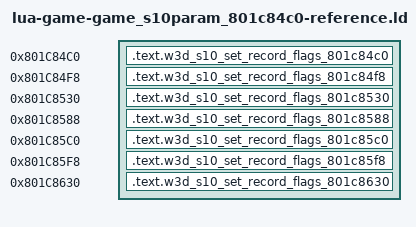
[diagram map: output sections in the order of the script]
/* Generated reference-only placements. All bodies are source-built. */
OUTPUT_FORMAT("elf32-powerpc")
OUTPUT_ARCH(powerpc)
ENTRY(w3d_s10_set_record_flags_801c84c0)
_SDA_BASE_ = 0x804b2540;
_SDA2_BASE_ = 0x804c2540;
SECTIONS {
  .text.w3d_s10_set_record_flags_801c84c0 0x801c84c0 : { *(.text.w3d_s10_set_record_flags_801c84c0) }
  .text.w3d_s10_set_record_flags_801c84f8 0x801c84f8 : { *(.text.w3d_s10_set_record_flags_801c84f8) }
  .text.w3d_s10_set_record_flags_801c8530 0x801c8530 : { *(.text.w3d_s10_set_record_flags_801c8530) }
  .text.w3d_s10_set_record_flags_801c8588 0x801c8588 : { *(.text.w3d_s10_set_record_flags_801c8588) }
  .text.w3d_s10_set_record_flags_801c85c0 0x801c85c0 : { *(.text.w3d_s10_set_record_flags_801c85c0) }
  .text.w3d_s10_set_record_flags_801c85f8 0x801c85f8 : { *(.text.w3d_s10_set_record_flags_801c85f8) }
  .text.w3d_s10_set_record_flags_801c8630 0x801c8630 : { *(.text.w3d_s10_set_record_flags_801c8630) }
  /DISCARD/ : { *(.text*) *(.rodata*) *(.data*) *(.bss*) *(.sdata*) *(.sbss*) *(.comment) }
}
